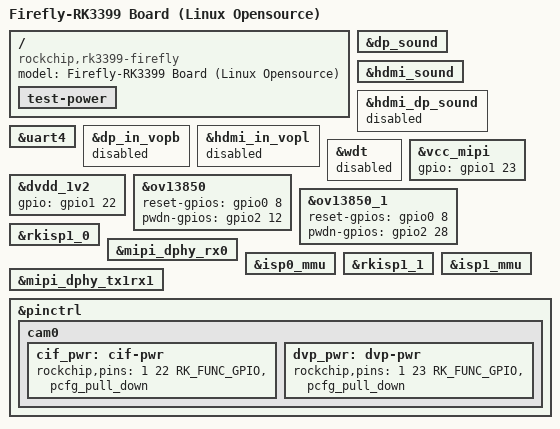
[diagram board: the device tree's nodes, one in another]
/*
 * Copyright (c) 2016 Fuzhou Rockchip Electronics Co., Ltd
 *
 * This file is dual-licensed: you can use it either under the terms
 * of the GPL or the X11 license, at your option. Note that this dual
 * licensing only applies to this file, and not this project as a
 * whole.
 *
 *  a) This file is free software; you can redistribute it and/or
 *     modify it under the terms of the GNU General Public License as
 *     published by the Free Software Foundation; either version 2 of the
 *     License, or (at your option) any later version.
 *
 *     This file is distributed in the hope that it will be useful,
 *     but WITHOUT ANY WARRANTY; without even the implied warranty of
 *     MERCHANTABILITY or FITNESS FOR A PARTICULAR PURPOSE.  See the
 *     GNU General Public License for more details.
 *
 * Or, alternatively,
 *
 *  b) Permission is hereby granted, free of charge, to any person
 *     obtaining a copy of this software and associated documentation
 *     files (the "Software"), to deal in the Software without
 *     restriction, including without limitation the rights to use,
 *     copy, modify, merge, publish, distribute, sublicense, and/or
 *     sell copies of the Software, and to permit persons to whom the
 *     Software is furnished to do so, subject to the following
 *     conditions:
 *
 *     The above copyright notice and this permission notice shall be
 *     included in all copies or substantial portions of the Software.
 *
 *     THE SOFTWARE IS PROVIDED "AS IS", WITHOUT WARRANTY OF ANY KIND,
 *     EXPRESS OR IMPLIED, INCLUDING BUT NOT LIMITED TO THE WARRANTIES
 *     OF MERCHANTABILITY, FITNESS FOR A PARTICULAR PURPOSE AND
 *     NONINFRINGEMENT. IN NO EVENT SHALL THE AUTHORS OR COPYRIGHT
 *     HOLDERS BE LIABLE FOR ANY CLAIM, DAMAGES OR OTHER LIABILITY,
 *     WHETHER IN AN ACTION OF CONTRACT, TORT OR OTHERWISE, ARISING
 *     FROM, OUT OF OR IN CONNECTION WITH THE SOFTWARE OR THE USE OR
 *     OTHER DEALINGS IN THE SOFTWARE.
 */

/dts-v1/;

#include "rk3399-firefly-port.dtsi"

/ {
	model = "Firefly-RK3399 Board (Linux Opensource)";
	compatible = "rockchip,rk3399-firefly", "rockchip,rk3399";

	test-power {
		status = "okay";
	};
};

&dp_sound {
	status = "okay";
};

&hdmi_sound {
	status = "okay";
};

&hdmi_dp_sound {
	status = "disabled";
};

&uart4 {
	status = "okay";
};

&dp_in_vopb {
	status = "disabled";
};

&hdmi_in_vopl {
	status = "disabled";
};

&wdt {
	status = "disabled";
};

&vcc_mipi {
	gpio = <&gpio1 23 GPIO_ACTIVE_HIGH>;
	status = "okay";
};

&dvdd_1v2 {
	gpio = <&gpio1 22 GPIO_ACTIVE_HIGH>;
	status = "okay";
};

&ov13850 {
	reset-gpios = <&gpio0 8 GPIO_ACTIVE_HIGH>;
	pwdn-gpios = <&gpio2 12 GPIO_ACTIVE_HIGH>;
	status = "okay";
};

&ov13850_1 {
	reset-gpios = <&gpio0 8 GPIO_ACTIVE_HIGH>;
	pwdn-gpios = <&gpio2 28 GPIO_ACTIVE_HIGH>;
	status = "okay";
};


&rkisp1_0 {
	status = "okay";
};

&mipi_dphy_rx0 {
	status = "okay";
};

&isp0_mmu {
	status = "okay";
};

&rkisp1_1 {
	status = "okay";
};

&mipi_dphy_tx1rx1 {
	status = "okay";
};

&isp1_mmu {
	status = "okay";
};

&pinctrl {
	
	cam0 {
                cif_pwr: cif-pwr {
                        rockchip,pins = <1 22 RK_FUNC_GPIO &pcfg_pull_down>;
                };

                dvp_pwr: dvp-pwr {
                        rockchip,pins = <1 23 RK_FUNC_GPIO &pcfg_pull_down>;
                };
        };

};

